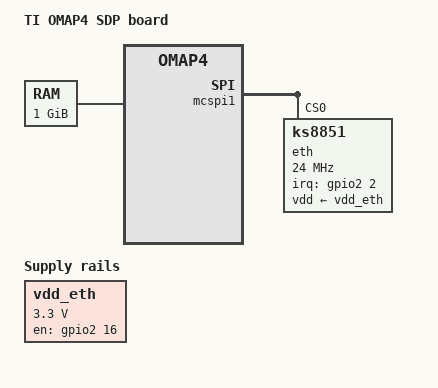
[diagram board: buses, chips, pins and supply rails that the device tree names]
/*
 * Copyright (C) 2011 Texas Instruments Incorporated - http://www.ti.com/
 *
 * This program is free software; you can redistribute it and/or modify
 * it under the terms of the GNU General Public License version 2 as
 * published by the Free Software Foundation.
 */
/dts-v1/;

/include/ "omap4.dtsi"

/ {
	model = "TI OMAP4 SDP board";
	compatible = "ti,omap4-sdp", "ti,omap4430", "ti,omap4";

	memory {
		device_type = "memory";
		reg = <0x80000000 0x40000000>; /* 1 GB */
	};

	vdd_eth: fixedregulator@0 {
		compatible = "regulator-fixed";
		regulator-name = "VDD_ETH";
		regulator-min-microvolt = <3300000>;
		regulator-max-microvolt = <3300000>;
		gpio = <&gpio2 16 0>;  /* gpio line 48 */
		enable-active-high;
		regulator-boot-on;
	};
};

&mcspi1 {
	eth@0 {
		compatible = "ks8851";
		spi-max-frequency = <24000000>;
		reg = <0>;
		interrupt-parent = <&gpio2>;
		interrupts = <2>; /* gpio line 34 */
		vdd-supply = <&vdd_eth>;
	};
};
